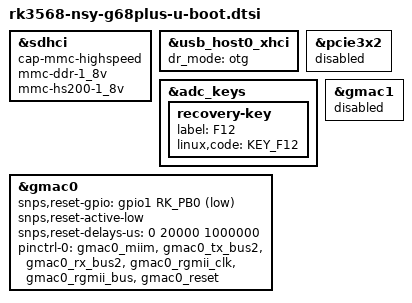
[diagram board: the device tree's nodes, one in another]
// SPDX-License-Identifier: (GPL-2.0+ OR MIT)

#include "rk356x-u-boot.dtsi"

&sdhci {
	cap-mmc-highspeed;
	mmc-ddr-1_8v;
	mmc-hs200-1_8v;
};

&usb_host0_xhci {
	dr_mode = "otg";
};

&pcie3x2 {
	status = "disabled";
};

&adc_keys {
	recovery-key {
		label = "F12";
		linux,code = <KEY_F12>;
	};
};

&gmac0 {
	status = "okay";
	snps,reset-gpio = <&gpio1 RK_PB0 GPIO_ACTIVE_LOW>;
	snps,reset-active-low;
	snps,reset-delays-us = <0 20000 1000000>;
	pinctrl-names = "default";
	pinctrl-0 = <&gmac0_miim &gmac0_tx_bus2 &gmac0_rx_bus2 &gmac0_rgmii_clk &gmac0_rgmii_bus &gmac0_reset>;
};

&gmac1 {
	status = "disabled";
};
